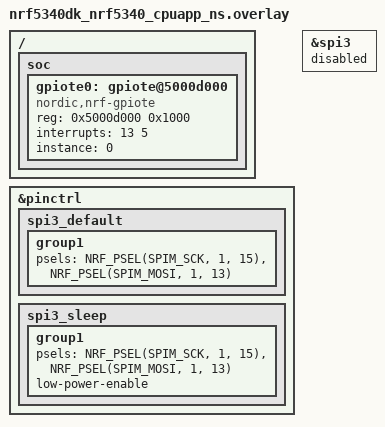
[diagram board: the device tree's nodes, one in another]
/* Copyright (c) 2022 Nordic Semiconductor ASA
 *
 * SPDX-License-Identifier: LicenseRef-Nordic-5-Clause
 */

/ {
	soc {
		/* Secure GPIOTE instance to be used with TFM */
		gpiote0: gpiote@5000d000 {
			compatible = "nordic,nrf-gpiote";
			reg = <0x5000d000 0x1000>;
			interrupts = <13 5>;
			status = "okay";
			instance = <0>;
		};
	};
};

&pinctrl {
	spi3_default: spi3_default {
		group1 {
			psels = <NRF_PSEL(SPIM_SCK, 1, 15)>,
				<NRF_PSEL(SPIM_MOSI, 1, 13)>;
		};
	};

	spi3_sleep: spi3_sleep {
		group1 {
			psels = <NRF_PSEL(SPIM_SCK, 1, 15)>,
				<NRF_PSEL(SPIM_MOSI, 1, 13)>;
			low-power-enable;
		};
	};
};

&spi3 {
	/* Disabled in non-secure image. */
	status = "disabled";
};
